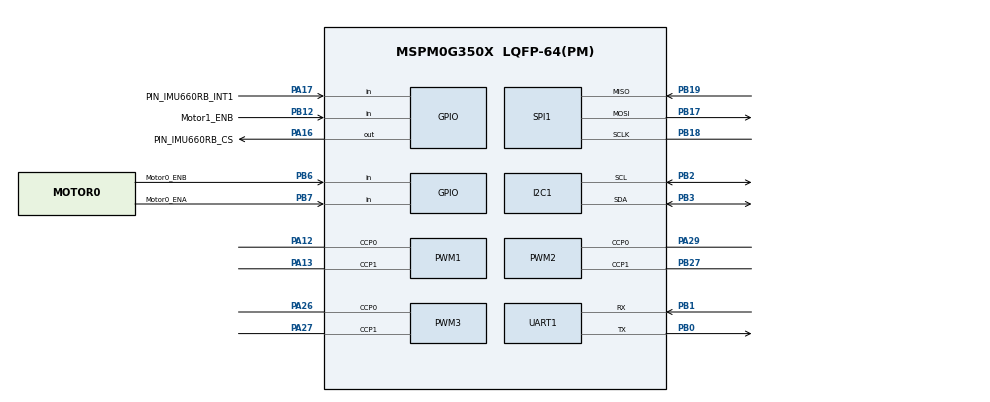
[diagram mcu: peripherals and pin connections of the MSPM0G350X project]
/**
 * @cliArgs --device "MSPM0G350X" --part "Default" --package "LQFP-64(PM)" --product "mspm0_sdk@2.05.00.05"
 * @versions {"tool":"1.27.1+4634"}
 */

/**
 * Import the modules used in this configuration.
 */
const GPIO   = scripting.addModule("/ti/driverlib/GPIO", {}, false);
const GPIO1  = GPIO.addInstance();
const GPIO2  = GPIO.addInstance();
const GPIO3  = GPIO.addInstance();
const GPIO4  = GPIO.addInstance();
const GPIO5  = GPIO.addInstance();
const GPIO6  = GPIO.addInstance();
const GPIO7  = GPIO.addInstance();
const GPIO8  = GPIO.addInstance();
const I2C    = scripting.addModule("/ti/driverlib/I2C", {}, false);
const I2C1   = I2C.addInstance();
const PWM    = scripting.addModule("/ti/driverlib/PWM", {}, false);
const PWM1   = PWM.addInstance();
const PWM2   = PWM.addInstance();
const PWM3   = PWM.addInstance();
const SPI    = scripting.addModule("/ti/driverlib/SPI", {}, false);
const SPI1   = SPI.addInstance();
const SYSCTL = scripting.addModule("/ti/driverlib/SYSCTL");
const TIMER  = scripting.addModule("/ti/driverlib/TIMER", {}, false);
const TIMER1 = TIMER.addInstance();
const UART   = scripting.addModule("/ti/driverlib/UART", {}, false);
const UART1  = UART.addInstance();

/**
 * Write custom configuration values to the imported modules.
 */
const divider7       = system.clockTree["PLL_PDIV"];
divider7.divideValue = 2;

const divider9       = system.clockTree["UDIV"];
divider9.divideValue = 2;

const multiplier2         = system.clockTree["PLL_QDIV"];
multiplier2.multiplyValue = 5;

const mux8       = system.clockTree["HSCLKMUX"];
mux8.inputSelect = "HSCLKMUX_SYSPLL2X";

GPIO1.$name                               = "GPIO_IMU660RB";
GPIO1.associatedPins.create(2);
GPIO1.associatedPins[0].$name             = "PIN_IMU660RB_CS";
GPIO1.associatedPins[0].assignedPort      = "PORTA";
GPIO1.associatedPins[0].assignedPin       = "16";
GPIO1.associatedPins[0].pin.$assign       = "PA16";
GPIO1.associatedPins[1].$name             = "PIN_IMU660RB_INT1";
GPIO1.associatedPins[1].direction         = "INPUT";
GPIO1.associatedPins[1].interruptEn       = true;
GPIO1.associatedPins[1].interruptPriority = "3";
GPIO1.associatedPins[1].polarity          = "RISE";
GPIO1.associatedPins[1].assignedPort      = "PORTA";
GPIO1.associatedPins[1].assignedPin       = "17";
GPIO1.associatedPins[1].pin.$assign       = "PA17";

const Board = scripting.addModule("/ti/driverlib/Board", {}, false);

GPIO2.$name                          = "Motor_01";
GPIO2.associatedPins.create(6);
GPIO2.associatedPins[0].assignedPort = "PORTB";
GPIO2.associatedPins[0].$name        = "Motor0_GPIO";
GPIO2.associatedPins[0].assignedPin  = "8";
GPIO2.associatedPins[1].assignedPort = "PORTB";
GPIO2.associatedPins[1].$name        = "Motor1_GPIO";
GPIO2.associatedPins[1].assignedPin  = "9";
GPIO2.associatedPins[2].$name        = "Motor0_ENA";
GPIO2.associatedPins[2].direction    = "INPUT";
GPIO2.associatedPins[2].interruptEn  = true;
GPIO2.associatedPins[2].polarity     = "RISE";
GPIO2.associatedPins[2].assignedPort = "PORTB";
GPIO2.associatedPins[2].assignedPin  = "7";
GPIO2.associatedPins[2].pin.$assign  = "PB7";
GPIO2.associatedPins[3].$name        = "Motor0_ENB";
GPIO2.associatedPins[3].direction    = "INPUT";
GPIO2.associatedPins[3].assignedPort = "PORTB";
GPIO2.associatedPins[3].assignedPin  = "6";
GPIO2.associatedPins[3].pin.$assign  = "PB6";
GPIO2.associatedPins[4].$name        = "Motor1_ENA";
GPIO2.associatedPins[4].direction    = "INPUT";
GPIO2.associatedPins[4].interruptEn  = true;
GPIO2.associatedPins[4].polarity     = "RISE";
GPIO2.associatedPins[4].assignedPin  = "13";
GPIO2.associatedPins[4].assignedPort = "PORTB";
GPIO2.associatedPins[5].direction    = "INPUT";
GPIO2.associatedPins[5].assignedPin  = "12";
GPIO2.associatedPins[5].$name        = "Motor1_ENB";
GPIO2.associatedPins[5].assignedPort = "PORTB";
GPIO2.associatedPins[5].pin.$assign  = "PB12";

GPIO3.$name                          = "Motor_23";
GPIO3.associatedPins.create(6);
GPIO3.associatedPins[0].$name        = "Motor2";
GPIO3.associatedPins[0].assignedPort = "PORTB";
GPIO3.associatedPins[0].assignedPin  = "26";
GPIO3.associatedPins[1].$name        = "Motor3";
GPIO3.associatedPins[1].assignedPort = "PORTB";
GPIO3.associatedPins[1].assignedPin  = "23";
GPIO3.associatedPins[2].assignedPort = "PORTB";
GPIO3.associatedPins[2].$name        = "Motor_2_ENA";
GPIO3.associatedPins[2].assignedPin  = "15";
GPIO3.associatedPins[2].direction    = "INPUT";
GPIO3.associatedPins[2].interruptEn  = true;
GPIO3.associatedPins[2].polarity     = "RISE";
GPIO3.associatedPins[3].$name        = "Motor_2_ENB";
GPIO3.associatedPins[3].assignedPort = "PORTB";
GPIO3.associatedPins[3].assignedPin  = "16";
GPIO3.associatedPins[3].direction    = "INPUT";
GPIO3.associatedPins[4].$name        = "Motor_3_ENA";
GPIO3.associatedPins[4].assignedPort = "PORTB";
GPIO3.associatedPins[4].assignedPin  = "4";
GPIO3.associatedPins[4].direction    = "INPUT";
GPIO3.associatedPins[4].interruptEn  = true;
GPIO3.associatedPins[4].polarity     = "RISE";
GPIO3.associatedPins[5].$name        = "Motor_3_ENB";
GPIO3.associatedPins[5].assignedPort = "PORTB";
GPIO3.associatedPins[5].assignedPin  = "5";
GPIO3.associatedPins[5].direction    = "INPUT";

GPIO4.$name                              = "Button";
GPIO4.port                               = "PORTA";
GPIO4.associatedPins.create(4);
GPIO4.associatedPins[0].assignedPin      = "28";
GPIO4.associatedPins[0].$name            = "PIN_28";
GPIO4.associatedPins[0].direction        = "INPUT";
GPIO4.associatedPins[0].internalResistor = "PULL_UP";
GPIO4.associatedPins[1].$name            = "PIN_31";
GPIO4.associatedPins[1].assignedPin      = "31";
GPIO4.associatedPins[1].direction        = "INPUT";
GPIO4.associatedPins[1].internalResistor = "PULL_UP";
GPIO4.associatedPins[2].$name            = "PIN_8";
GPIO4.associatedPins[2].assignedPin      = "8";
GPIO4.associatedPins[2].direction        = "INPUT";
GPIO4.associatedPins[2].internalResistor = "PULL_UP";
GPIO4.associatedPins[3].$name            = "PIN_9";
GPIO4.associatedPins[3].assignedPin      = "9";
GPIO4.associatedPins[3].direction        = "INPUT";
GPIO4.associatedPins[3].internalResistor = "PULL_UP";

GPIO5.$name                              = "GPIO_Tracker";
GPIO5.associatedPins.create(8);
GPIO5.associatedPins[0].$name            = "PIN_0";
GPIO5.associatedPins[0].internalResistor = "PULL_UP";
GPIO5.associatedPins[0].assignedPort     = "PORTA";
GPIO5.associatedPins[0].assignedPin      = "24";
GPIO5.associatedPins[0].direction        = "INPUT";
GPIO5.associatedPins[1].$name            = "PIN_1";
GPIO5.associatedPins[1].assignedPort     = "PORTA";
GPIO5.associatedPins[1].assignedPin      = "25";
GPIO5.associatedPins[1].internalResistor = "PULL_UP";
GPIO5.associatedPins[1].direction        = "INPUT";
GPIO5.associatedPins[2].$name            = "PIN_2";
GPIO5.associatedPins[2].assignedPort     = "PORTB";
GPIO5.associatedPins[2].assignedPin      = "24";
GPIO5.associatedPins[2].internalResistor = "PULL_UP";
GPIO5.associatedPins[2].direction        = "INPUT";
GPIO5.associatedPins[3].$name            = "PIN_3";
GPIO5.associatedPins[3].assignedPort     = "PORTB";
GPIO5.associatedPins[3].assignedPin      = "25";
GPIO5.associatedPins[3].internalResistor = "PULL_UP";
GPIO5.associatedPins[3].direction        = "INPUT";
GPIO5.associatedPins[4].$name            = "PIN_4";
GPIO5.associatedPins[4].assignedPort     = "PORTA";
GPIO5.associatedPins[4].assignedPin      = "22";
GPIO5.associatedPins[4].internalResistor = "PULL_UP";
GPIO5.associatedPins[4].direction        = "INPUT";
GPIO5.associatedPins[5].$name            = "PIN_5";
GPIO5.associatedPins[5].assignedPort     = "PORTB";
GPIO5.associatedPins[5].assignedPin      = "20";
GPIO5.associatedPins[5].internalResistor = "PULL_UP";
GPIO5.associatedPins[5].direction        = "INPUT";
GPIO5.associatedPins[6].$name            = "PIN_6";
GPIO5.associatedPins[6].assignedPort     = "PORTA";
GPIO5.associatedPins[6].assignedPin      = "15";
GPIO5.associatedPins[6].internalResistor = "PULL_UP";
GPIO5.associatedPins[6].direction        = "INPUT";
GPIO5.associatedPins[7].$name            = "PIN_7";
GPIO5.associatedPins[7].assignedPort     = "PORTA";
GPIO5.associatedPins[7].assignedPin      = "14";
GPIO5.associatedPins[7].internalResistor = "PULL_UP";
GPIO5.associatedPins[7].direction        = "INPUT";

GPIO6.$name                          = "GPIO_Mos";
GPIO6.associatedPins.create(2);
GPIO6.associatedPins[0].$name        = "PIN_B22";
GPIO6.associatedPins[0].assignedPort = "PORTB";
GPIO6.associatedPins[0].assignedPin  = "22";
GPIO6.associatedPins[1].$name        = "PIN_B21";
GPIO6.associatedPins[1].assignedPort = "PORTB";
GPIO6.associatedPins[1].assignedPin  = "21";

GPIO7.$name                          = "GPIO_duoyv";
GPIO7.associatedPins.create(4);
GPIO7.associatedPins[0].$name        = "PIN_10";
GPIO7.associatedPins[0].assignedPort = "PORTB";
GPIO7.associatedPins[0].assignedPin  = "11";
GPIO7.associatedPins[1].$name        = "PIN_11";
GPIO7.associatedPins[1].assignedPort = "PORTB";
GPIO7.associatedPins[1].assignedPin  = "14";
GPIO7.associatedPins[2].$name        = "PIN_12";
GPIO7.associatedPins[2].assignedPort = "PORTB";
GPIO7.associatedPins[2].assignedPin  = "10";
GPIO7.associatedPins[3].$name        = "PIN_13";
GPIO7.associatedPins[3].assignedPort = "PORTA";
GPIO7.associatedPins[3].assignedPin  = "7";

GPIO8.$name                          = "GPIO_CR";
GPIO8.associatedPins[0].$name        = "PIN_A330";
GPIO8.associatedPins[0].assignedPort = "PORTA";
GPIO8.associatedPins[0].assignedPin  = "30";

I2C1.$name                             = "IICOLED";
I2C1.basicEnableController             = true;
I2C1.basicControllerStandardBusSpeed   = "Fast";
I2C1.peripheral.$assign                = "I2C1";
I2C1.peripheral.sdaPin.$assign         = "PB3";
I2C1.peripheral.sclPin.$assign         = "PB2";
I2C1.sdaPinConfig.hideOutputInversion  = scripting.forceWrite(false);
I2C1.sdaPinConfig.onlyInternalResistor = scripting.forceWrite(false);
I2C1.sdaPinConfig.passedPeripheralType = scripting.forceWrite("Digital");
I2C1.sdaPinConfig.$name                = "ti_driverlib_gpio_GPIOPinGeneric3";
I2C1.sclPinConfig.hideOutputInversion  = scripting.forceWrite(false);
I2C1.sclPinConfig.onlyInternalResistor = scripting.forceWrite(false);
I2C1.sclPinConfig.passedPeripheralType = scripting.forceWrite("Digital");
I2C1.sclPinConfig.$name                = "ti_driverlib_gpio_GPIOPinGeneric4";

PWM1.timerStartTimer                    = true;
PWM1.$name                              = "Motor_PWM_01";
PWM1.timerCount                         = 40000;
PWM1.peripheral.$assign                 = "TIMG0";
PWM1.peripheral.ccp0Pin.$assign         = "PA12";
PWM1.peripheral.ccp1Pin.$assign         = "PA13";
PWM1.PWM_CHANNEL_0.$name                = "ti_driverlib_pwm_PWMTimerCC0";
PWM1.PWM_CHANNEL_0.dutyCycle            = 30;
PWM1.PWM_CHANNEL_1.$name                = "ti_driverlib_pwm_PWMTimerCC1";
PWM1.PWM_CHANNEL_1.dutyCycle            = 60;
PWM1.ccp0PinConfig.direction            = scripting.forceWrite("OUTPUT");
PWM1.ccp0PinConfig.hideOutputInversion  = scripting.forceWrite(false);
PWM1.ccp0PinConfig.onlyInternalResistor = scripting.forceWrite(false);
PWM1.ccp0PinConfig.passedPeripheralType = scripting.forceWrite("Digital");
PWM1.ccp0PinConfig.$name                = "ti_driverlib_gpio_GPIOPinGeneric5";
PWM1.ccp1PinConfig.direction            = scripting.forceWrite("OUTPUT");
PWM1.ccp1PinConfig.hideOutputInversion  = scripting.forceWrite(false);
PWM1.ccp1PinConfig.onlyInternalResistor = scripting.forceWrite(false);
PWM1.ccp1PinConfig.passedPeripheralType = scripting.forceWrite("Digital");
PWM1.ccp1PinConfig.$name                = "ti_driverlib_gpio_GPIOPinGeneric6";

PWM2.timerCount                         = 4000;
PWM2.timerStartTimer                    = true;
PWM2.$name                              = "Motor_PWM_23";
PWM2.peripheral.$assign                 = "TIMG6";
PWM2.peripheral.ccp0Pin.$assign         = "PA29";
PWM2.peripheral.ccp1Pin.$assign         = "PB27";
PWM2.PWM_CHANNEL_0.$name                = "ti_driverlib_pwm_PWMTimerCC2";
PWM2.PWM_CHANNEL_0.dutyCycle            = 30;
PWM2.PWM_CHANNEL_1.$name                = "ti_driverlib_pwm_PWMTimerCC3";
PWM2.PWM_CHANNEL_1.dutyCycle            = 60;
PWM2.ccp0PinConfig.direction            = scripting.forceWrite("OUTPUT");
PWM2.ccp0PinConfig.hideOutputInversion  = scripting.forceWrite(false);
PWM2.ccp0PinConfig.onlyInternalResistor = scripting.forceWrite(false);
PWM2.ccp0PinConfig.passedPeripheralType = scripting.forceWrite("Digital");
PWM2.ccp0PinConfig.$name                = "ti_driverlib_gpio_GPIOPinGeneric7";
PWM2.ccp1PinConfig.direction            = scripting.forceWrite("OUTPUT");
PWM2.ccp1PinConfig.hideOutputInversion  = scripting.forceWrite(false);
PWM2.ccp1PinConfig.onlyInternalResistor = scripting.forceWrite(false);
PWM2.ccp1PinConfig.passedPeripheralType = scripting.forceWrite("Digital");
PWM2.ccp1PinConfig.$name                = "ti_driverlib_gpio_GPIOPinGeneric8";

PWM3.$name                              = "PWM_Servo";
PWM3.clockPrescale                      = 100;
PWM3.timerCount                         = 16000;
PWM3.timerStartTimer                    = true;
PWM3.peripheral.$assign                 = "TIMG7";
PWM3.peripheral.ccp0Pin.$assign         = "PA26";
PWM3.peripheral.ccp1Pin.$assign         = "PA27";
PWM3.PWM_CHANNEL_0.$name                = "ti_driverlib_pwm_PWMTimerCC4";
PWM3.PWM_CHANNEL_0.ccValue              = 16000;
PWM3.PWM_CHANNEL_1.$name                = "ti_driverlib_pwm_PWMTimerCC5";
PWM3.PWM_CHANNEL_1.ccValue              = 16000;
PWM3.ccp0PinConfig.direction            = scripting.forceWrite("OUTPUT");
PWM3.ccp0PinConfig.hideOutputInversion  = scripting.forceWrite(false);
PWM3.ccp0PinConfig.onlyInternalResistor = scripting.forceWrite(false);
PWM3.ccp0PinConfig.passedPeripheralType = scripting.forceWrite("Digital");
PWM3.ccp0PinConfig.$name                = "ti_driverlib_gpio_GPIOPinGeneric11";
PWM3.ccp1PinConfig.direction            = scripting.forceWrite("OUTPUT");
PWM3.ccp1PinConfig.hideOutputInversion  = scripting.forceWrite(false);
PWM3.ccp1PinConfig.onlyInternalResistor = scripting.forceWrite(false);
PWM3.ccp1PinConfig.passedPeripheralType = scripting.forceWrite("Digital");
PWM3.ccp1PinConfig.$name                = "ti_driverlib_gpio_GPIOPinGeneric12";

SPI1.$name                              = "SPI_IMU660RB";
SPI1.chipSelect                         = ["2"];
SPI1.frameFormat                        = "MOTO3";
SPI1.sclkPinConfig.direction            = scripting.forceWrite("OUTPUT");
SPI1.sclkPinConfig.onlyInternalResistor = scripting.forceWrite(false);
SPI1.sclkPinConfig.passedPeripheralType = scripting.forceWrite("Digital");
SPI1.sclkPinConfig.$name                = "ti_driverlib_gpio_GPIOPinGeneric0";
SPI1.mosiPinConfig.direction            = scripting.forceWrite("OUTPUT");
SPI1.mosiPinConfig.hideOutputInversion  = scripting.forceWrite(false);
SPI1.mosiPinConfig.onlyInternalResistor = scripting.forceWrite(false);
SPI1.mosiPinConfig.passedPeripheralType = scripting.forceWrite("Digital");
SPI1.mosiPinConfig.$name                = "ti_driverlib_gpio_GPIOPinGeneric1";
SPI1.misoPinConfig.onlyInternalResistor = scripting.forceWrite(false);
SPI1.misoPinConfig.passedPeripheralType = scripting.forceWrite("Digital");
SPI1.misoPinConfig.$name                = "ti_driverlib_gpio_GPIOPinGeneric2";
SPI1.peripheral.$assign                 = "SPI0";
SPI1.peripheral.sclkPin.$assign         = "PB18";
SPI1.peripheral.mosiPin.$assign         = "PB17";
SPI1.peripheral.misoPin.$assign         = "PB19";

SYSCTL.forceDefaultClkConfig = true;
SYSCTL.clockTreeEn           = true;

TIMER1.$name              = "TIMER_0";
TIMER1.timerClkPrescale   = 100;
TIMER1.timerMode          = "PERIODIC";
TIMER1.timerPeriod        = "1ms";
TIMER1.timerStartTimer    = true;
TIMER1.peripheral.$assign = "TIMA0";

UART1.$name                    = "UART_0";
UART1.targetBaudRate           = 115200;
UART1.peripheral.$assign       = "UART0";
UART1.peripheral.rxPin.$assign = "PB1";
UART1.peripheral.txPin.$assign = "PB0";
UART1.txPinConfig.$name        = "ti_driverlib_gpio_GPIOPinGeneric9";
UART1.rxPinConfig.$name        = "ti_driverlib_gpio_GPIOPinGeneric10";

/**
 * Pinmux solution for unlocked pins/peripherals. This ensures that minor changes to the automatic solver in a future
 * version of the tool will not impact the pinmux you originally saw.  These lines can be completely deleted in order to
 * re-solve from scratch.
 */
Board.peripheral.$suggestSolution            = "DEBUGSS";
Board.peripheral.swclkPin.$suggestSolution   = "PA20";
Board.peripheral.swdioPin.$suggestSolution   = "PA19";
GPIO2.associatedPins[0].pin.$suggestSolution = "PB8";
GPIO2.associatedPins[1].pin.$suggestSolution = "PB9";
GPIO2.associatedPins[4].pin.$suggestSolution = "PB13";
GPIO3.associatedPins[0].pin.$suggestSolution = "PB26";
GPIO3.associatedPins[1].pin.$suggestSolution = "PB23";
GPIO3.associatedPins[2].pin.$suggestSolution = "PB15";
GPIO3.associatedPins[3].pin.$suggestSolution = "PB16";
GPIO3.associatedPins[4].pin.$suggestSolution = "PB4";
GPIO3.associatedPins[5].pin.$suggestSolution = "PB5";
GPIO4.associatedPins[0].pin.$suggestSolution = "PA28";
GPIO4.associatedPins[1].pin.$suggestSolution = "PA31";
GPIO4.associatedPins[2].pin.$suggestSolution = "PA8";
GPIO4.associatedPins[3].pin.$suggestSolution = "PA9";
GPIO5.associatedPins[0].pin.$suggestSolution = "PA24";
GPIO5.associatedPins[1].pin.$suggestSolution = "PA25";
GPIO5.associatedPins[2].pin.$suggestSolution = "PB24";
GPIO5.associatedPins[3].pin.$suggestSolution = "PB25";
GPIO5.associatedPins[4].pin.$suggestSolution = "PA22";
GPIO5.associatedPins[5].pin.$suggestSolution = "PB20";
GPIO5.associatedPins[6].pin.$suggestSolution = "PA15";
GPIO5.associatedPins[7].pin.$suggestSolution = "PA14";
GPIO6.associatedPins[0].pin.$suggestSolution = "PB22";
GPIO6.associatedPins[1].pin.$suggestSolution = "PB21";
GPIO7.associatedPins[0].pin.$suggestSolution = "PB11";
GPIO7.associatedPins[1].pin.$suggestSolution = "PB14";
GPIO7.associatedPins[2].pin.$suggestSolution = "PB10";
GPIO7.associatedPins[3].pin.$suggestSolution = "PA7";
GPIO8.associatedPins[0].pin.$suggestSolution = "PA30";
